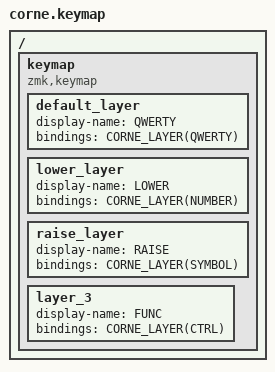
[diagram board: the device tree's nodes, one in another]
/*
 * Classic 42-key Corne. Keys live in corne_shared.dtsi - edit them there.
 *
 * Key positions:
 *  0  1  2  3  4  5      6  7  8  9 10 11
 * 12 13 14 15 16 17     18 19 20 21 22 23
 * 24 25 26 27 28 29     30 31 32 33 34 35
 *          36 37 38     39 40 41
 */

#define COMBO_J 19
#define COMBO_K 20

#include "corne_shared.dtsi"

#define CORNE_LAYER(N) \
    N##_L0 N##_R0 \
    N##_L1 N##_R1 \
    N##_L2 N##_R2 \
    N##_LT N##_RT

/ {
    keymap {
        compatible = "zmk,keymap";

        default_layer {
            display-name = "QWERTY";
            bindings = <CORNE_LAYER(QWERTY)>;
        };

        lower_layer {
            display-name = "LOWER";
            bindings = <CORNE_LAYER(NUMBER)>;
        };

        raise_layer {
            display-name = "RAISE";
            bindings = <CORNE_LAYER(SYMBOL)>;
        };

        layer_3 {
            display-name = "FUNC";
            bindings = <CORNE_LAYER(CTRL)>;
        };
    };
};
